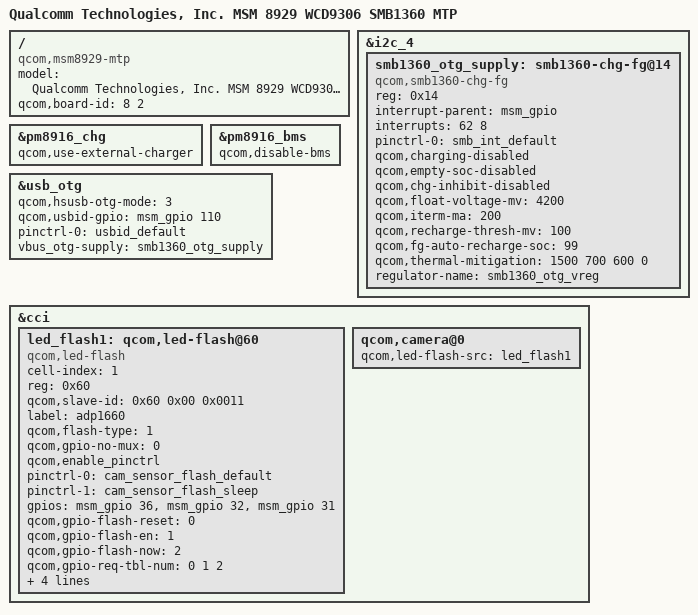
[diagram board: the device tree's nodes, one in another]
/*
 * Copyright (c) 2015, The Linux Foundation. All rights reserved.
 *
 * This program is free software; you can redistribute it and/or modify
 * it under the terms of the GNU General Public License version 2 and
 * only version 2 as published by the Free Software Foundation.
 *
 * This program is distributed in the hope that it will be useful,
 * but WITHOUT ANY WARRANTY; without even the implied warranty of
 * MERCHANTABILITY or FITNESS FOR A PARTICULAR PURPOSE.  See the
 * GNU General Public License for more details.
 */

/dts-v1/;

#include "msm8929.dtsi"
#include "msm8939-mtp.dtsi"
#include "msm8939-audio-external_codec.dtsi"

/ {
	model = "Qualcomm Technologies, Inc. MSM 8929 WCD9306 SMB1360 MTP";
	compatible = "qcom,msm8929-mtp", "qcom,msm8929", "qcom,mtp";
	qcom,board-id = <8 2>;
};

&i2c_4 {
	smb1360_otg_supply: smb1360-chg-fg@14 {
		compatible = "qcom,smb1360-chg-fg";
		reg = <0x14>;
		interrupt-parent = <&msm_gpio>;
		interrupts = <62 8>;
		pinctrl-names = "default";
		pinctrl-0 = <&smb_int_default>;
		qcom,charging-disabled;
		qcom,empty-soc-disabled;
		qcom,chg-inhibit-disabled;
		qcom,float-voltage-mv = <4200>;
		qcom,iterm-ma = <200>;
		qcom,recharge-thresh-mv = <100>;
		qcom,fg-auto-recharge-soc = <99>;
		qcom,thermal-mitigation = <1500 700 600 0>;
		regulator-name = "smb1360_otg_vreg";
	};
};

&pm8916_chg {
	status = "ok";
	qcom,use-external-charger;
};

&pm8916_bms {
	status = "ok";
	qcom,disable-bms;
};

&usb_otg {
	qcom,hsusb-otg-mode = <3>;
	qcom,usbid-gpio = <&msm_gpio 110 0>;
	pinctrl-names = "default";
	pinctrl-0 = <&usbid_default>;
	vbus_otg-supply = <&smb1360_otg_supply>;
};

&cci {
	led_flash1: qcom,led-flash@60 {
		cell-index = <1>;
		reg = <0x60>;
		qcom,slave-id = <0x60 0x00 0x0011>;
		compatible = "qcom,led-flash";
		label = "adp1660";
		qcom,flash-type = <1>;
		qcom,gpio-no-mux = <0>;
		qcom,enable_pinctrl;
		pinctrl-names = "cam_flash_default", "cam_flash_suspend";
		pinctrl-0 = <&cam_sensor_flash_default>;
		pinctrl-1 = <&cam_sensor_flash_sleep>;
		gpios = <&msm_gpio 36 0>,
				<&msm_gpio 32 0>,
				<&msm_gpio 31 0>;
		qcom,gpio-flash-reset = <0>;
		qcom,gpio-flash-en = <1>;
		qcom,gpio-flash-now = <2>;
		qcom,gpio-req-tbl-num = <0 1 2>;
		qcom,gpio-req-tbl-flags = <0 0 0>;
		qcom,gpio-req-tbl-label = "FLASH_RST",
				"FLASH_EN",
				"FLASH_NOW";
		qcom,cci-master = <0>;
	};

	qcom,camera@0 {
		qcom,led-flash-src = <&led_flash1>;
	};
};
